AUTOSAR XML (schema 4-3-0)
package /DBCImport/CANTP
  can tp config CanTpConfig_BCAN: communication-cluster=BCAN, can-tp-ecu=SCM
    can tp channel CanTpChannel0: channel-id=0, channel-mode=HALF-DUPLEX-MODE
    can tp channel CanTpChannel2: channel-id=2, channel-mode=HALF-DUPLEX-MODE
    tp-connections:
      addressing-format=STANDARD, can-tp-channel=CanTpChannel0, data-pdu=NPdu_BCAN_RWPC_GST, flow-control-pdu=NPdu_BCAN_GST_RWPC, max-block-size=0, padding-activation=true, ta-type=PHYSICAL, tp-sdu=DcmIPdu_BCAN_RWPC_GST
      addressing-format=STANDARD, can-tp-channel=CanTpChannel0, data-pdu=NPdu_BCAN_GST_RWPC, flow-control-pdu=NPdu_BCAN_RWPC_GST, max-block-size=0, padding-activation=true, ta-type=PHYSICAL, tp-sdu=DcmIPdu_BCAN_GST_RWPC
      addressing-format=STANDARD, can-tp-channel=CanTpChannel2, data-pdu=NPdu_BCAN_GST_ALL, max-block-size=0, padding-activation=true, ta-type=FUNCTIONAL, tp-sdu=DcmIPdu_BCAN_GST_ALL
    can tp node SCM: connector=Conn_SCM_BCAN
package /DBCImport/SWCComposition
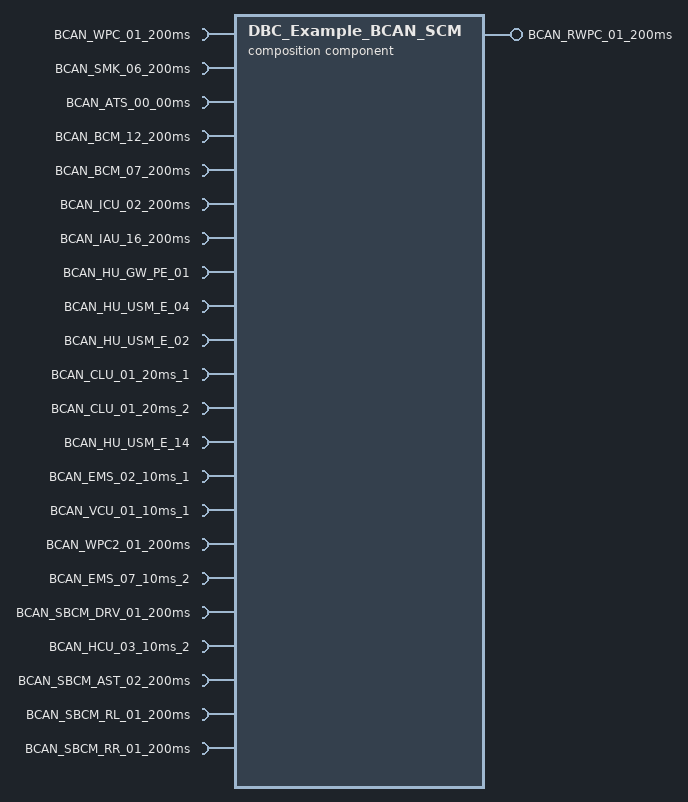
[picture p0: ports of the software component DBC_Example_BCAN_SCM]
  composition sw component type DBC_Example_BCAN_SCM
    provide port BCAN_RWPC_01_200ms: provided-interface=BCAN_RWPC_01_200ms
    22 x require port:
      BCAN_WPC_01_200ms: required-interface=BCAN_WPC_01_200ms
      BCAN_SMK_06_200ms: required-interface=BCAN_SMK_06_200ms
      BCAN_ATS_00_00ms: required-interface=BCAN_ATS_00_00ms
      BCAN_BCM_12_200ms: required-interface=BCAN_BCM_12_200ms
      BCAN_BCM_07_200ms: required-interface=BCAN_BCM_07_200ms
      BCAN_ICU_02_200ms: required-interface=BCAN_ICU_02_200ms
      BCAN_IAU_16_200ms: required-interface=BCAN_IAU_16_200ms
      BCAN_HU_GW_PE_01: required-interface=BCAN_HU_GW_PE_01
      BCAN_HU_USM_E_04: required-interface=BCAN_HU_USM_E_04
      BCAN_HU_USM_E_02: required-interface=BCAN_HU_USM_E_02
      BCAN_CLU_01_20ms_1: required-interface=BCAN_CLU_01_20ms_1
      BCAN_CLU_01_20ms_2: required-interface=BCAN_CLU_01_20ms_2
      BCAN_HU_USM_E_14: required-interface=BCAN_HU_USM_E_14
      BCAN_EMS_02_10ms_1: required-interface=BCAN_EMS_02_10ms_1
      BCAN_VCU_01_10ms_1: required-interface=BCAN_VCU_01_10ms_1
      BCAN_WPC2_01_200ms: required-interface=BCAN_WPC2_01_200ms
      BCAN_EMS_07_10ms_2: required-interface=BCAN_EMS_07_10ms_2
      BCAN_SBCM_DRV_01_200ms: required-interface=BCAN_SBCM_DRV_01_200ms
      BCAN_HCU_03_10ms_2: required-interface=BCAN_HCU_03_10ms_2
      BCAN_SBCM_AST_02_200ms: required-interface=BCAN_SBCM_AST_02_200ms
      BCAN_SBCM_RL_01_200ms: required-interface=BCAN_SBCM_RL_01_200ms
      BCAN_SBCM_RR_01_200ms: required-interface=BCAN_SBCM_RR_01_200ms
package /DBCImport/CLUSTERS
  can cluster BCAN: baudrate=500000, protocol-name=CAN, speed=500
    can physical channel BCAN: comm-connectors=Conn_SCM_BCAN
      frame CanFrame_BCAN_WPC_01_200ms: id 0x44B, frame-length=8, can-addressing-mode=STANDARD, can-fd-frame-support=false  # [PE] Periodic and On Event
        pdu ISignalIPdu_BCAN_WPC_01_200ms: length=8, minimum-delay=0.02, transmission-mode-true-timing={cyclic-timing={time-offset=0.0, time-period=0.2}, event-controlled-timing={number-of-repetitions=3, repetition-period=0.04}}
          signal ISignal_BCAN_WPC_01_200ms_WPC_IndSyncVal: start 40, 3 bit, little-endian, init-value=0, base-type=uint8, compu-method=ISignal_BCAN_WPC_01_200ms_WPC_IndSyncVal, transfer-property=TRIGGERED-ON-CHANGE
          signal ISignal_BCAN_WPC_01_200ms_USM_CmdWPCIndSta: start 43, 3 bit, little-endian, init-value=2, base-type=uint8, compu-method=ISignal_BCAN_WPC_01_200ms_USM_CmdWPCIndSta, transfer-property=TRIGGERED-ON-CHANGE
      frame CanFrame_BCAN_SMK_06_200ms: id 0x445, frame-length=8, can-addressing-mode=STANDARD, can-fd-frame-support=false  # [PE] Periodic and On Event
        pdu ISignalIPdu_BCAN_SMK_06_200ms: length=8, minimum-delay=0.02, transmission-mode-true-timing={cyclic-timing={time-offset=0.0, time-period=0.2}, event-controlled-timing={number-of-repetitions=3, repetition-period=0.04}}
          signal ISignal_BCAN_SMK_06_200ms_LFAnt_SrchSta: start 42, 2 bit, little-endian, init-value=0, base-type=uint8, compu-method=ISignal_BCAN_SMK_06_200ms_LFAnt_SrchSta, transfer-property=TRIGGERED-ON-CHANGE  # LFAntenna_SearchingStatus ##2G##SMK - SMKmsg19 - C_LFSearchingOn
      frame CanFrame_BCAN_ATS_00_00ms: id 0x447, frame-length=8, can-addressing-mode=STANDARD, can-fd-frame-support=false  # [EC] On Event and On Change
        pdu ISignalIPdu_BCAN_ATS_00_00ms: length=8, minimum-delay=0.02, transmission-mode-true-timing=event-controlled-timing={number-of-repetitions=3, repetition-period=0.04}
          signal ISignal_BCAN_ATS_00_00ms_ATS_RWPC_RWPCNValueSet: start 2, 3 bit, little-endian, init-value=0, base-type=uint8, compu {0=Default, 1=Off, 2=On, 3=Invalid, phys=raw for raw 0}, transfer-property=TRIGGERED-ON-CHANGE  # Rear Wireless Phone Charger ON/OFF Request
      frame CanFrame_BCAN_BCM_12_200ms: id 0x442, frame-length=8, can-addressing-mode=STANDARD, can-fd-frame-support=false  # [PE] Periodic and On Event
        pdu ISignalIPdu_BCAN_BCM_12_200ms: length=8, minimum-delay=0.02, transmission-mode-true-timing={cyclic-timing={time-offset=0.0, time-period=0.2}, event-controlled-timing={number-of-repetitions=3, repetition-period=0.04}}
          signal ISignal_BCAN_BCM_12_200ms_BCM_SmkOptTyp: start 24, 2 bit, little-endian, init-value=0, base-type=uint8, compu-method=ISignal_BCAN_BCM_12_200ms_BCM_SmkOptTyp, transfer-property=TRIGGERED-ON-CHANGE  # BCM_SmkOptionType ##2G##BCM - BCMmsg17 - C_SMKOption
      frame CanFrame_BCAN_BCM_07_200ms: id 0x41A, frame-length=8, can-addressing-mode=STANDARD, can-fd-frame-support=false  # [PE] Periodic and On Event
        pdu ISignalIPdu_BCAN_BCM_07_200ms: length=8, minimum-delay=0.02, transmission-mode-true-timing={cyclic-timing={time-offset=0.0, time-period=0.2}, event-controlled-timing={number-of-repetitions=3, repetition-period=0.04}}
          signal ISignal_BCAN_BCM_07_200ms_Lamp_IntTailLmpOnReq: start 36, 2 bit, little-endian, init-value=0, base-type=uint8, compu {0=Off, 1=On, 2=Not Used, 3=Error Indicator, phys=raw for raw 0}, transfer-property=TRIGGERED-ON-CHANGE  # Lamp_InternalTailLampOnRequest ##2G##BCM - BCMmsg19 - C_IntTailOn
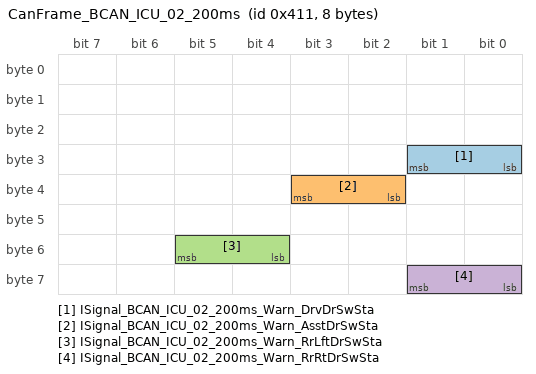
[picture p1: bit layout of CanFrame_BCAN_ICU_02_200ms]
      frame CanFrame_BCAN_ICU_02_200ms: id 0x411, frame-length=8, can-addressing-mode=STANDARD, can-fd-frame-support=false  # [PE] Periodic and On Event
        pdu ISignalIPdu_BCAN_ICU_02_200ms: length=8, minimum-delay=0.02, transmission-mode-true-timing={cyclic-timing={time-offset=0.0, time-period=0.2}, event-controlled-timing={number-of-repetitions=3, repetition-period=0.04}}
          signal ISignal_BCAN_ICU_02_200ms_Warn_DrvDrSwSta: start 24, 2 bit, little-endian, init-value=0, base-type=uint8, compu {0=Close, 1=Open, 2=Not Used, 3=Error Indicator, phys=raw for raw 0}, transfer-property=TRIGGERED-ON-CHANGE  # DoorLock_DriverDoorSwitchStatus ##2G## - - C_DrvDrSw,CF_Gway_DrvDrSw,Warn_DrvDrSwSta
          signal ISignal_BCAN_ICU_02_200ms_Warn_AsstDrSwSta: start 34, 2 bit, little-endian, init-value=0, base-type=uint8, compu {0=Close, 1=Open, 2=Not Used, 3=Error Indicator, phys=raw for raw 0}, transfer-property=TRIGGERED-ON-CHANGE  # Warn_AssistDoorSwitchStatus ##2G## - - C_AstDrSw,CF_Gway_AstDrSw,Warn_AsstDrSwSta
          signal ISignal_BCAN_ICU_02_200ms_Warn_RrLftDrSwSta: start 52, 2 bit, little-endian, init-value=0, base-type=uint8, compu {0=Close, 1=Open, 2=Not Used, 3=Error Indicator, phys=raw for raw 0}, transfer-property=TRIGGERED-ON-CHANGE  # Warn_RearLeftDoorSwitchStatus ##2G## - - C_RLDrSw,CF_Gway_RLDrSw,Warn_RrLftDrSwSta
          signal ISignal_BCAN_ICU_02_200ms_Warn_RrRtDrSwSta: start 56, 2 bit, little-endian, init-value=0, base-type=uint8, compu {0=Close, 1=Open, 2=Not Used, 3=Error Indicator, phys=raw for raw 0}, transfer-property=TRIGGERED-ON-CHANGE  # Warn_RearRightDoorSwitchStatus ##2G## - - C_RRDrSw,CF_Gway_RRDrSw,Warn_RrRtDrSwSta
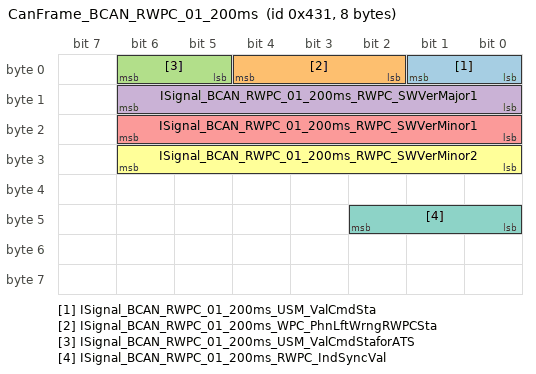
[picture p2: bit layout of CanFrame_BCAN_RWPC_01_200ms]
      frame CanFrame_BCAN_RWPC_01_200ms: id 0x431, frame-length=8, can-addressing-mode=STANDARD, can-fd-frame-support=false  # [PE] Periodic and On Event
        pdu ISignalIPdu_BCAN_RWPC_01_200ms: length=8, minimum-delay=0.02, transmission-mode-true-timing={cyclic-timing={time-offset=0.0, time-period=0.2}, event-controlled-timing={number-of-repetitions=3, repetition-period=0.04}}
          signal ISignal_BCAN_RWPC_01_200ms_USM_ValCmdSta: start 0, 2 bit, little-endian, init-value=0, base-type=uint8, compu {0=Default, 1=Off(Disable), 2=On(Enable), 3=Invalid, phys=raw for raw 0}, transfer-property=TRIGGERED-ON-CHANGE  # USM_ValueCommandStatus
          signal ISignal_BCAN_RWPC_01_200ms_WPC_PhnLftWrngRWPCSta: start 2, 3 bit, little-endian, init-value=0, base-type=uint8, compu-method=ISignal_BCAN_RWPC_01_200ms_WPC_PhnLftWrngRWPCSta, transfer-property=TRIGGERED-ON-CHANGE  # WPC_PhoneLeftWaringRWPCStatus
          signal ISignal_BCAN_RWPC_01_200ms_USM_ValCmdStaforATS: start 5, 2 bit, little-endian, init-value=0, base-type=uint8, compu {0=Default, 1=Off(Disable), 2=On(Enable), 3=Invalid, phys=raw for raw 0}, transfer-property=TRIGGERED-ON-CHANGE  # USM_ValueCommandStatus
          signal ISignal_BCAN_RWPC_01_200ms_RWPC_SWVerMajor1: start 8, 7 bit, little-endian, init-value=0, base-type=uint8, compu-method=ISignal_BCAN_RWPC_01_200ms_RWPC_SWVerMajor1, transfer-property=TRIGGERED-ON-CHANGE  # First Word(ASCII) in RWPC S/W Ver
          signal ISignal_BCAN_RWPC_01_200ms_RWPC_SWVerMinor1: start 16, 7 bit, little-endian, init-value=0, base-type=uint8, compu-method=ISignal_BCAN_RWPC_01_200ms_RWPC_SWVerMinor1, transfer-property=TRIGGERED-ON-CHANGE  # Second Word(ASCII) in RWPC S/W Ver
          signal ISignal_BCAN_RWPC_01_200ms_RWPC_SWVerMinor2: start 24, 7 bit, little-endian, init-value=0, base-type=uint8, compu-method=ISignal_BCAN_RWPC_01_200ms_RWPC_SWVerMinor2, transfer-property=TRIGGERED-ON-CHANGE  # Third Word(ASCII) in RWPC S/W Ver
          signal ISignal_BCAN_RWPC_01_200ms_RWPC_IndSyncVal: start 40, 3 bit, little-endian, init-value=0, base-type=uint8, compu-method=ISignal_BCAN_RWPC_01_200ms_RWPC_IndSyncVal, transfer-property=TRIGGERED-ON-CHANGE
      frame CanFrame_BCAN_IAU_16_200ms: id 0x434, frame-length=8, can-addressing-mode=STANDARD, can-fd-frame-support=false  # [PE] Periodic and On Event
        pdu ISignalIPdu_BCAN_IAU_16_200ms: length=8, minimum-delay=0.02, transmission-mode-true-timing={cyclic-timing={time-offset=0.0, time-period=0.2}, event-controlled-timing={number-of-repetitions=3, repetition-period=0.04}}
          signal ISignal_BCAN_IAU_16_200ms_IAU_ProfileIDRVal: start 10, 4 bit, little-endian, init-value=0, base-type=uint8, compu-method=ISignal_BCAN_IAU_16_200ms_IAU_ProfileIDRVal, transfer-property=TRIGGERED-ON-CHANGE  # This signal Indicate the Current detected Profile ID by IAU.
      frame CanFrame_BCAN_HU_GW_PE_01: id 0x4D8, frame-length=8, can-addressing-mode=STANDARD, can-fd-frame-support=false  # [PE] Periodic and On Event
        pdu ISignalIPdu_BCAN_HU_GW_PE_01: length=8, minimum-delay=0.02, transmission-mode-true-timing={cyclic-timing={time-offset=0.0, time-period=0.2}, event-controlled-timing={number-of-repetitions=3, repetition-period=0.04}}
          signal ISignal_BCAN_HU_GW_PE_01_CF_AVN_ProfileIDRValue: start 40, 4 bit, little-endian, init-value=15, base-type=uint8, compu-method=ISignal_BCAN_HU_GW_PE_01_CF_AVN_ProfileIDRValue, transfer-property=TRIGGERED-ON-CHANGE  # This signal is User ID value in H/Unit.
      frame CanFrame_BCAN_HU_USM_E_04: id 0x4AB, frame-length=8, can-addressing-mode=STANDARD, can-fd-frame-support=false  # [EC] On Event and On Change
        pdu ISignalIPdu_BCAN_HU_USM_E_04: length=8, minimum-delay=0.02, transmission-mode-true-timing=event-controlled-timing={number-of-repetitions=3, repetition-period=0.04}
          signal ISignal_BCAN_HU_USM_E_04_CF_AVN_CluUSMReset: start 62, 2 bit, little-endian, init-value=0, base-type=uint8, compu {0=Default, 1=USM Reset, 2=Reserved, 3=Invalid, phys=raw for raw 0}, transfer-property=TRIGGERED-ON-CHANGE  # Request to reset all USM service
      frame CanFrame_BCAN_HU_USM_E_02: id 0x4A9, frame-length=8, can-addressing-mode=STANDARD, can-fd-frame-support=false  # [EC] On Event and On Change
        pdu ISignalIPdu_BCAN_HU_USM_E_02: length=8, minimum-delay=0.02, transmission-mode-true-timing=event-controlled-timing={number-of-repetitions=3, repetition-period=0.04}
          signal ISignal_BCAN_HU_USM_E_02_CF_Gway_RWPCNValueSet: start 40, 2 bit, little-endian, init-value=0, base-type=uint8, compu {0=Default, 1=Off, 2=On, 3=Invalid, phys=raw for raw 0}, transfer-property=TRIGGERED-ON-CHANGE  # Rear Wireless Phone Charger ON/OFF Request
      frame CanFrame_BCAN_CLU_01_20ms_1: id 0x681AA01, frame-length=8, can-addressing-mode=EXTENDED, can-fd-frame-support=false  # [P] Periodic
        pdu ISignalIPdu_BCAN_CLU_01_20ms_1: length=8, minimum-delay=0.02, transmission-mode-true-timing=cyclic-timing={time-offset=0.0, time-period=0.1}
          signal ISignal_BCAN_CLU_01_20ms_1_CLU_DtntOutSta: start 28, 2 bit, little-endian, init-value=0, base-type=uint8, compu-method=ISignal_BCAN_CLU_01_20ms_1_CLU_DtntOutSta, transfer-property=PENDING  # CLU_DetentOutStatus
          signal ISignal_BCAN_CLU_01_20ms_1_CLU_RhstaLvlSta: start 43, 5 bit, little-endian, init-value=0, base-type=uint8, compu-method=ISignal_BCAN_CLU_01_20ms_1_CLU_RhstaLvlSta, transfer-property=PENDING  # CLU_RheostatLevelStatus
      frame CanFrame_BCAN_CLU_01_20ms_2: id 0x681AA02, frame-length=8, can-addressing-mode=EXTENDED, can-fd-frame-support=false  # [P] Periodic
        pdu ISignalIPdu_BCAN_CLU_01_20ms_2: length=8, minimum-delay=0.02, transmission-mode-true-timing=cyclic-timing={time-offset=0.0, time-period=0.1}
          signal ISignal_BCAN_CLU_01_20ms_2_CLU_DisSpdVal_KPH: start 0, 9 bit, little-endian, init-value=0, base-type=uint16, compu {511=Error, phys=raw for raw 0; unit km/h}, unit=km/h, transfer-property=PENDING  # CLU_DisplaySpeedValue_KPH
          signal ISignal_BCAN_CLU_01_20ms_2_CLU_AutoBrightSta: start 15, 8 bit, little-endian, init-value=0, base-type=uint8, compu-method=ISignal_BCAN_CLU_01_20ms_2_CLU_AutoBrightSta, transfer-property=PENDING  # CLU_AutoBrightStatus
      frame CanFrame_BCAN_HU_USM_E_14: id 0x1EB, frame-length=8, can-addressing-mode=STANDARD, can-fd-frame-support=false  # [EC] On Event and On Change
        pdu ISignalIPdu_BCAN_HU_USM_E_14: length=8, minimum-delay=0.02, transmission-mode-true-timing=event-controlled-timing={number-of-repetitions=3, repetition-period=0.04}
          signal ISignal_BCAN_HU_USM_E_14_CF_Gway_WPCAnimationNvalueSet: start 40, 3 bit, little-endian, init-value=0, base-type=uint8, compu-method=ISignal_BCAN_HU_USM_E_14_CF_Gway_WPCAnimationNvalueSet, transfer-property=TRIGGERED-ON-CHANGE
      frame CanFrame_BCAN_EMS_02_10ms_1: id 0x4010001, frame-length=8, can-addressing-mode=EXTENDED, can-fd-frame-support=false  # [P] Periodic
        pdu ISignalIPdu_BCAN_EMS_02_10ms_1: length=8, minimum-delay=0.02, transmission-mode-true-timing=cyclic-timing={time-offset=0.0, time-period=0.05}
          signal ISignal_BCAN_EMS_02_10ms_1_ENG_EngSta: start 61, 3 bit, little-endian, init-value=0, base-type=uint8, compu-method=ISignal_BCAN_EMS_02_10ms_1_ENG_EngSta, transfer-property=PENDING  # ENG_EngineStatus ##2G##EMS - EMS16 - ENG_STAT
      frame CanFrame_BCAN_VCU_01_10ms_1: id 0xC03501, frame-length=8, can-addressing-mode=EXTENDED, can-fd-frame-support=false  # [P] Periodic
        pdu ISignalIPdu_BCAN_VCU_01_10ms_1: length=8, minimum-delay=0.02, transmission-mode-true-timing=cyclic-timing={time-offset=0.0, time-period=0.05}
          signal ISignal_BCAN_VCU_01_10ms_1_VCU_EvDrvRdySta: start 28, 2 bit, little-endian, init-value=0, base-type=uint8, compu-method=ISignal_BCAN_VCU_01_10ms_1_VCU_EvDrvRdySta, transfer-property=PENDING  # VCU_EvDriveReadyStatus ##2G##VCU - VCU1 - CF_Vcu_EvRdy
      frame CanFrame_BCAN_WPC2_01_200ms: id 0x33E, frame-length=8, can-addressing-mode=STANDARD, can-fd-frame-support=false  # [PE] Periodic and On Event
        pdu ISignalIPdu_BCAN_WPC2_01_200ms: length=8, minimum-delay=0.02, transmission-mode-true-timing={cyclic-timing={time-offset=0.0, time-period=0.2}, event-controlled-timing={number-of-repetitions=3, repetition-period=0.04}}
          signal ISignal_BCAN_WPC2_01_200ms_WPC2_IndSyncVal: start 40, 3 bit, little-endian, init-value=0, base-type=uint8, compu-method=ISignal_BCAN_WPC2_01_200ms_WPC2_IndSyncVal, transfer-property=TRIGGERED-ON-CHANGE
      frame CanFrame_BCAN_EMS_07_10ms_2: id 0x4010502, frame-length=8, can-addressing-mode=EXTENDED, can-fd-frame-support=false  # [P] Periodic
        pdu ISignalIPdu_BCAN_EMS_07_10ms_2: length=8, minimum-delay=0.02, transmission-mode-true-timing=cyclic-timing={time-offset=0.0, time-period=0.05}
          signal ISignal_BCAN_EMS_07_10ms_2_HEV_EngOpSta: start 28, 3 bit, little-endian, init-value=0, base-type=uint8, compu-method=ISignal_BCAN_EMS_07_10ms_2_HEV_EngOpSta, transfer-property=PENDING  # HEV_EngineOperatingStatus
      frame CanFrame_BCAN_SBCM_DRV_01_200ms: id 0x31F, frame-length=8, can-addressing-mode=STANDARD, can-fd-frame-support=false  # [PE] Periodic and On Event
        pdu ISignalIPdu_BCAN_SBCM_DRV_01_200ms: length=8, minimum-delay=0.02, transmission-mode-true-timing={cyclic-timing={time-offset=0.0, time-period=0.2}, event-controlled-timing={number-of-repetitions=3, repetition-period=0.04}}
          signal ISignal_BCAN_SBCM_DRV_01_200ms_Warn_DrvDrSwSta_SBCM: start 20, 2 bit, little-endian, init-value=0, base-type=uint8, compu {0=Close, 1=Open, 2=RESERVED, 3=Error Indicator, phys=raw for raw 0}, transfer-property=TRIGGERED-ON-CHANGE  # DoorLock_DriverDoorSwitchStatus ##2G## - - C_DrvDrSw,CF_Gway_DrvDrSw,Warn_DrvDrSwSta
          signal ISignal_BCAN_SBCM_DRV_01_200ms_Latch_TypeOption_DRV: start 36, 2 bit, little-endian, init-value=0, base-type=uint8, compu {0=Off, 1=On, 2=RESERVED, 3=Error Indicator, phys=raw for raw 0}, transfer-property=TRIGGERED-ON-CHANGE
      frame CanFrame_BCAN_HCU_03_10ms_2: id 0x3C0FA02, frame-length=8, can-addressing-mode=EXTENDED, can-fd-frame-support=false  # [P] Periodic
        pdu ISignalIPdu_BCAN_HCU_03_10ms_2: length=8, minimum-delay=0.02, transmission-mode-true-timing=cyclic-timing={time-offset=0.0, time-period=0.05}
          signal ISignal_BCAN_HCU_03_10ms_2_HCU_HevRdySta: start 6, 2 bit, little-endian, init-value=0, base-type=uint8, compu-method=ISignal_BCAN_HCU_03_10ms_2_HCU_HevRdySta, transfer-property=PENDING  # HCU_HybridVehicleReadyStatus ##2G##HCU - HCU1 - CF_Hcu_HevRdy
      frame CanFrame_BCAN_RWPC_GST: id 0x72C, frame-length=8, can-addressing-mode=STANDARD, can-fd-frame-support=false
        dcm i pdu DcmIPdu_BCAN_RWPC_GST: length=8, diag-pdu-type=DIAG-RESPONSE
        n pdu NPdu_BCAN_RWPC_GST: length=8, meta-data-length=0
      frame CanFrame_BCAN_GST_RWPC: id 0x724, frame-length=8, can-addressing-mode=STANDARD, can-fd-frame-support=false
        dcm i pdu DcmIPdu_BCAN_GST_RWPC: length=8, diag-pdu-type=DIAG-REQUEST
        n pdu NPdu_BCAN_GST_RWPC: length=8, meta-data-length=0
      frame CanFrame_BCAN_SBCM_AST_02_200ms: id 0x35A, frame-length=8, can-addressing-mode=STANDARD, can-fd-frame-support=false  # [PE] Periodic and On Event
        pdu ISignalIPdu_BCAN_SBCM_AST_02_200ms: length=8, minimum-delay=0.02, transmission-mode-true-timing={cyclic-timing={time-offset=0.0, time-period=0.2}, event-controlled-timing={number-of-repetitions=3, repetition-period=0.04}}
          signal ISignal_BCAN_SBCM_AST_02_200ms_Warn_AsstDrSwSta_SBCM: start 20, 2 bit, little-endian, init-value=0, base-type=uint8, compu {0=Close, 1=Open, 2=RESERVED, 3=Error Indicator, phys=raw for raw 0}, transfer-property=TRIGGERED-ON-CHANGE  # Warn_AssistDoorSwitchStatus ##2G## - - C_AstDrSw,CF_Gway_AstDrSw,Warn_AsstDrSwSta
      frame CanFrame_BCAN_SBCM_RL_01_200ms: id 0x35E, frame-length=8, can-addressing-mode=STANDARD, can-fd-frame-support=false  # [PE] Periodic and On Event
        pdu ISignalIPdu_BCAN_SBCM_RL_01_200ms: length=8, minimum-delay=0.02, transmission-mode-true-timing={cyclic-timing={time-offset=0.0, time-period=0.2}, event-controlled-timing={number-of-repetitions=3, repetition-period=0.04}}
          signal ISignal_BCAN_SBCM_RL_01_200ms_Warn_RrLftDrSwSta_SBCM: start 16, 2 bit, little-endian, init-value=0, base-type=uint8, compu {0=Close, 1=Open, 2=RESERVED, 3=Error Indicator, phys=raw for raw 0}, transfer-property=TRIGGERED-ON-CHANGE  # Warn_RearLeftDoorSwitchStatus ##2G## - - C_RLDrSw,CF_Gway_RLDrSw,Warn_RrLftDrSwSta
      frame CanFrame_BCAN_GST_ALL: id 0x7DF, frame-length=8, can-addressing-mode=STANDARD, can-fd-frame-support=false
        dcm i pdu DcmIPdu_BCAN_GST_ALL: length=8
        n pdu NPdu_BCAN_GST_ALL: length=8, meta-data-length=0
      frame CanFrame_BCAN_SBCM_RR_01_200ms: id 0x389, frame-length=8, can-addressing-mode=STANDARD, can-fd-frame-support=false  # [PE] Periodic and On Event
        pdu ISignalIPdu_BCAN_SBCM_RR_01_200ms: length=8, minimum-delay=0.02, transmission-mode-true-timing={cyclic-timing={time-offset=0.0, time-period=0.2}, event-controlled-timing={number-of-repetitions=3, repetition-period=0.04}}
          signal ISignal_BCAN_SBCM_RR_01_200ms_Warn_RrRtDrSwSta_SBCM: start 16, 2 bit, little-endian, init-value=0, base-type=uint8, compu {0=Close, 1=Open, 2=RESERVED, 3=Error Indicator, phys=raw for raw 0}, transfer-property=TRIGGERED-ON-CHANGE  # Warn_RearRightDoorSwitchStatus ##2G## - - C_RRDrSw,CF_Gway_RRDrSw,Warn_RrRtDrSwSta
      frame CanFrame_BCAN_NM_WPC2: id 0x515, frame-length=8, can-addressing-mode=STANDARD, can-fd-frame-support=false
        user defined pdu UserDefinedPdu_BCAN_NM_WPC2: length=8, cdd-type=OsekNm
      frame CanFrame_BCAN_NM_PSB: id 0x541, frame-length=8, can-addressing-mode=STANDARD, can-fd-frame-support=false
        user defined pdu UserDefinedPdu_BCAN_NM_PSB: length=8, cdd-type=OsekNm
      frame CanFrame_BCAN_NM_SHVU_RR: id 0x52B, frame-length=8, can-addressing-mode=STANDARD, can-fd-frame-support=false
        user defined pdu UserDefinedPdu_BCAN_NM_SHVU_RR: length=8, cdd-type=OsekNm
      frame CanFrame_BCAN_NM_FCS: id 0x521, frame-length=8, can-addressing-mode=STANDARD, can-fd-frame-support=false
        user defined pdu UserDefinedPdu_BCAN_NM_FCS: length=8, cdd-type=OsekNm
      frame CanFrame_BCAN_NM_EMCU: id 0x511, frame-length=8, can-addressing-mode=STANDARD, can-fd-frame-support=false
        user defined pdu UserDefinedPdu_BCAN_NM_EMCU: length=8, cdd-type=OsekNm
      frame CanFrame_BCAN_NM_SLB: id 0x51B, frame-length=8, can-addressing-mode=STANDARD, can-fd-frame-support=false
        user defined pdu UserDefinedPdu_BCAN_NM_SLB: length=8, cdd-type=OsekNm
      frame CanFrame_BCAN_NM_GW_APSU: id 0x531, frame-length=8, can-addressing-mode=STANDARD, can-fd-frame-support=false
        user defined pdu UserDefinedPdu_BCAN_NM_GW_APSU: length=8, cdd-type=OsekNm
      frame CanFrame_BCAN_NM_GW_DLBCU: id 0x540, frame-length=8, can-addressing-mode=STANDARD, can-fd-frame-support=false
        user defined pdu UserDefinedPdu_BCAN_NM_GW_DLBCU: length=8, cdd-type=OsekNm
      frame CanFrame_BCAN_NM_RCM: id 0x53D, frame-length=8, can-addressing-mode=STANDARD, can-fd-frame-support=false
        user defined pdu UserDefinedPdu_BCAN_NM_RCM: length=8, cdd-type=OsekNm
      frame CanFrame_BCAN_NM_ARS: id 0x50A, frame-length=8, can-addressing-mode=STANDARD, can-fd-frame-support=false
        user defined pdu UserDefinedPdu_BCAN_NM_ARS: length=8, cdd-type=OsekNm
      frame CanFrame_BCAN_NM_CGW_CCU: id 0x570, frame-length=8, can-addressing-mode=STANDARD, can-fd-frame-support=false
        user defined pdu UserDefinedPdu_BCAN_NM_CGW_CCU: length=8, cdd-type=OsekNm
      frame CanFrame_BCAN_NM_GW_RLPSU: id 0x51C, frame-length=8, can-addressing-mode=STANDARD, can-fd-frame-support=false
        user defined pdu UserDefinedPdu_BCAN_NM_GW_RLPSU: length=8, cdd-type=OsekNm
      frame CanFrame_BCAN_NM_ATS: id 0x550, frame-length=8, can-addressing-mode=STANDARD, can-fd-frame-support=false
        user defined pdu UserDefinedPdu_BCAN_NM_ATS: length=8, cdd-type=OsekNm
      frame CanFrame_BCAN_NM_RLHV: id 0x534, frame-length=8, can-addressing-mode=STANDARD, can-fd-frame-support=false
        user defined pdu UserDefinedPdu_BCAN_NM_RLHV: length=8, cdd-type=OsekNm
      frame CanFrame_BCAN_NM_SGU: id 0x53E, frame-length=8, can-addressing-mode=STANDARD, can-fd-frame-support=false
        user defined pdu UserDefinedPdu_BCAN_NM_SGU: length=8, cdd-type=OsekNm
      frame CanFrame_BCAN_NM_PFSU: id 0x52D, frame-length=8, can-addressing-mode=STANDARD, can-fd-frame-support=false
        user defined pdu UserDefinedPdu_BCAN_NM_PFSU: length=8, cdd-type=OsekNm
      frame CanFrame_BCAN_NM_GW_RRPSU: id 0x51D, frame-length=8, can-addressing-mode=STANDARD, can-fd-frame-support=false
        user defined pdu UserDefinedPdu_BCAN_NM_GW_RRPSU: length=8, cdd-type=OsekNm
      frame CanFrame_BCAN_NM_ALBCU: id 0x544, frame-length=8, can-addressing-mode=STANDARD, can-fd-frame-support=false
        user defined pdu UserDefinedPdu_BCAN_NM_ALBCU: length=8, cdd-type=OsekNm
      frame CanFrame_BCAN_NM_DSAU: id 0x559, frame-length=8, can-addressing-mode=STANDARD, can-fd-frame-support=false
        user defined pdu UserDefinedPdu_BCAN_NM_DSAU: length=8, cdd-type=OsekNm
      frame CanFrame_BCAN_NM_SWRC: id 0x508, frame-length=8, can-addressing-mode=STANDARD, can-fd-frame-support=false
        user defined pdu UserDefinedPdu_BCAN_NM_SWRC: length=8, cdd-type=OsekNm
      frame CanFrame_BCAN_NM_SHVU_FR: id 0x52A, frame-length=8, can-addressing-mode=STANDARD, can-fd-frame-support=false
        user defined pdu UserDefinedPdu_BCAN_NM_SHVU_FR: length=8, cdd-type=OsekNm
      frame CanFrame_BCAN_NM_RCS: id 0x546, frame-length=8, can-addressing-mode=STANDARD, can-fd-frame-support=false
        user defined pdu UserDefinedPdu_BCAN_NM_RCS: length=8, cdd-type=OsekNm
      frame CanFrame_BCAN_NM_GW_DPSU: id 0x538, frame-length=8, can-addressing-mode=STANDARD, can-fd-frame-support=false
        user defined pdu UserDefinedPdu_BCAN_NM_GW_DPSU: length=8, cdd-type=OsekNm
      frame CanFrame_BCAN_NM_BLTN_CAM: id 0x548, frame-length=8, can-addressing-mode=STANDARD, can-fd-frame-support=false
        user defined pdu UserDefinedPdu_BCAN_NM_BLTN_CAM: length=8, cdd-type=OsekNm
      frame CanFrame_BCAN_NM_SCM: id 0x507, frame-length=8, can-addressing-mode=STANDARD, can-fd-frame-support=false
        user defined pdu UserDefinedPdu_BCAN_NM_SCM: length=8, cdd-type=OsekNm
      frame CanFrame_BCAN_NM_OHCL: id 0x554, frame-length=8, can-addressing-mode=STANDARD, can-fd-frame-support=false
        user defined pdu UserDefinedPdu_BCAN_NM_OHCL: length=8, cdd-type=OsekNm
      frame CanFrame_BCAN_NM_RWPC: id 0x51F, frame-length=8, can-addressing-mode=STANDARD, can-fd-frame-support=false
        user defined pdu UserDefinedPdu_BCAN_NM_RWPC: length=8, cdd-type=OsekNm
      frame CanFrame_BCAN_NM_RRHV: id 0x535, frame-length=8, can-addressing-mode=STANDARD, can-fd-frame-support=false
        user defined pdu UserDefinedPdu_BCAN_NM_RRHV: length=8, cdd-type=OsekNm
      frame CanFrame_BCAN_NM_WPC: id 0x51E, frame-length=8, can-addressing-mode=STANDARD, can-fd-frame-support=false
        user defined pdu UserDefinedPdu_BCAN_NM_WPC: length=8, cdd-type=OsekNm
      frame CanFrame_BCAN_NM_HOD: id 0x54A, frame-length=8, can-addressing-mode=STANDARD, can-fd-frame-support=false
        user defined pdu UserDefinedPdu_BCAN_NM_HOD: length=8, cdd-type=OsekNm
      frame CanFrame_BCAN_NM_ASAU: id 0x553, frame-length=8, can-addressing-mode=STANDARD, can-fd-frame-support=false
        user defined pdu UserDefinedPdu_BCAN_NM_ASAU: length=8, cdd-type=OsekNm
package /DBCImport/COMPUMETHODS
  compu method ISignal_BCAN_BCM_12_200ms_BCM_SmkOptTyp: 0=Non SMK Option, 1=SMK Option, 2=Not Used, 3=Error Indicator, phys=raw for raw 0
  compu method ISignal_BCAN_CLU_01_20ms_1_CLU_DtntOutSta: 0=Detent Off, 1=Detent On, 2=Not used, 3=Error Indicator, phys=raw for raw 0
  compu method ISignal_BCAN_CLU_01_20ms_1_CLU_RhstaLvlSta: 0=Reserved, 1..19=Step 1..Step 19, 20=Step 20 (Reset Value), 21=Step 21 (Detent), phys=raw for raw 0
  compu method ISignal_BCAN_CLU_01_20ms_2_CLU_AutoBrightSta: 0=Reserved (Not Used), 1=0x01~0xC8:Bright State (1~200 Step), 200=0x01~0xC8:Bright State (1~200 Step), phys=raw for raw 0
  compu method ISignal_BCAN_EMS_02_10ms_1_ENG_EngSta: 0=Engine Stop, 1=Cranking, 2=Stalled, 3=Running, 4=Reserved, 5=Reserved, 6=Reserved, 7=Fault, phys=raw for raw 0
  compu method ISignal_BCAN_EMS_07_10ms_2_HEV_EngOpSta: 0=ES(Engine Stop), 1=ST(Start), 2=IS(Idle speed), 3=PL(Part Load), 4=PU(Pull), 5=PUC(Fuel Cut off), phys=raw for raw 0
  compu method ISignal_BCAN_HCU_03_10ms_2_HCU_HevRdySta: 0=HEV not ready, 1=HEV Drivable, 2=Not used, 3=Error Indicator, phys=raw for raw 0
  compu method ISignal_BCAN_HU_GW_PE_01_CF_AVN_ProfileIDRValue: 0=Default, 1=Guest, 2..10=Profile 1..Profile 9, 11..14=RESERVED, 15=Invalid, phys=raw for raw 0
  compu method ISignal_BCAN_HU_USM_E_14_CF_Gway_WPCAnimationNvalueSet: 0=Default, 1=Type 1 (Animation Off), 2=Type 2 (Animation On), 3..6=Reserved, 7=Invalid, phys=raw for raw 0
  compu method ISignal_BCAN_IAU_16_200ms_IAU_ProfileIDRVal: 0=Default, 1=Guest, 2..10=Profile1..Profile9, 11..14=RESERVED, 15=INVALID, phys=raw for raw 0
  compu method ISignal_BCAN_RWPC_01_200ms_RWPC_IndSyncVal: 0=default, 1=off, 2=1st sync, 3=2nd sync, 4=3rd sync, 5=error off, 6=error on, 7=reserved, phys=raw for raw 0
  compu method ISignal_BCAN_RWPC_01_200ms_RWPC_SWVerMajor1: 0=0x0x0~0x7F:ASCII Code Value (HEX), 127=0x0x0~0x7F:ASCII Code Value (HEX), phys=raw for raw 0
  compu method ISignal_BCAN_RWPC_01_200ms_RWPC_SWVerMinor1: 0=0x0x0~0x7F:ASCII Code Value (HEX), 127=0x0x0~0x7F:ASCII Code Value (HEX), phys=raw for raw 0
  compu method ISignal_BCAN_RWPC_01_200ms_RWPC_SWVerMinor2: 0=0x0x0~0x7F:ASCII Code Value (HEX), 127=0x0x0~0x7F:ASCII Code Value (HEX), phys=raw for raw 0
  compu method ISignal_BCAN_RWPC_01_200ms_WPC_PhnLftWrngRWPCSta: 0=Off, 1=Cellphone on the pad, 2=Charging, 3=Charging complete, 4=Cellphone reminder, 5=Error, 6=NFC Card detected, 7=Invalid, phys=raw for raw 0
  compu method ISignal_BCAN_SMK_06_200ms_LFAnt_SrchSta: 0=Off, 1=On (LF Searching), 2=Not Used, 3=Error Indicator, phys=raw for raw 0
  compu method ISignal_BCAN_VCU_01_10ms_1_VCU_EvDrvRdySta: 0=None, 1=EV Drivable, 2=Not used, 3=Error Indicator, phys=raw for raw 0..3
  compu method ISignal_BCAN_WPC2_01_200ms_WPC2_IndSyncVal: 0=default, 1=off, 2=1st sync, 3=2nd sync, 4=3rd sync, 5=error off, 6=error on, 7=reserved, phys=raw for raw 0
  compu method ISignal_BCAN_WPC_01_200ms_USM_CmdWPCIndSta: 0=Default, 1=Type 1 (Animation Off), 2=Type 2 (Animation On), 3..6=RESERVED, 7=Invalid, phys=raw for raw 0
  compu method ISignal_BCAN_WPC_01_200ms_WPC_IndSyncVal: 0=default, 1=off, 2=1st sync, 3=2nd sync, 4=3rd sync, 5=error off, 6=error on, 7=reserved, phys=raw for raw 0
package /DBCImport/IPDUGROUPS
  i signal i pdu group ISignalIPduGroupRx_SCM_BCAN: communication-direction=IN, communication-mode=rx
    i-signal-i-pdus:
      ISignalIPdu_BCAN_WPC_01_200ms
      ISignalIPdu_BCAN_SMK_06_200ms
      ISignalIPdu_BCAN_ATS_00_00ms
      ISignalIPdu_BCAN_BCM_12_200ms
      ISignalIPdu_BCAN_BCM_07_200ms
      ISignalIPdu_BCAN_ICU_02_200ms
      ISignalIPdu_BCAN_IAU_16_200ms
      ISignalIPdu_BCAN_HU_GW_PE_01
      ISignalIPdu_BCAN_HU_USM_E_04
      ISignalIPdu_BCAN_HU_USM_E_02
      ISignalIPdu_BCAN_CLU_01_20ms_1
      ISignalIPdu_BCAN_CLU_01_20ms_2
      ISignalIPdu_BCAN_HU_USM_E_14
      ISignalIPdu_BCAN_EMS_02_10ms_1
      ISignalIPdu_BCAN_VCU_01_10ms_1
      ISignalIPdu_BCAN_WPC2_01_200ms
      ISignalIPdu_BCAN_EMS_07_10ms_2
      ISignalIPdu_BCAN_SBCM_DRV_01_200ms
      ISignalIPdu_BCAN_HCU_03_10ms_2
      ISignalIPdu_BCAN_SBCM_AST_02_200ms
      ISignalIPdu_BCAN_SBCM_RL_01_200ms
      ISignalIPdu_BCAN_SBCM_RR_01_200ms
  i signal i pdu group ISignalIPduGroupTx_SCM_BCAN: communication-direction=OUT, communication-mode=tx, i-signal-i-pdus=ISignalIPdu_BCAN_RWPC_01_200ms
package /DBCImport/INTERFACES
  23 x sender receiver interface:
    BCAN_ATS_00_00ms
      data ATS_RWPC_RWPCNValueSet: base-type=uint8, compu {0=Default, 1=Off, 2=On, 3=Invalid, phys=raw for raw 0}, type=uint8, init-value=0
    BCAN_BCM_07_200ms
      data Lamp_IntTailLmpOnReq: base-type=uint8, compu {0=Off, 1=On, 2=Not Used, 3=Error Indicator, phys=raw for raw 0}, type=uint8, init-value=0
    BCAN_BCM_12_200ms
      data BCM_SmkOptTyp: base-type=uint8, compu-method=ISignal_BCAN_BCM_12_200ms_BCM_SmkOptTyp, type=uint8, init-value=0
    BCAN_CLU_01_20ms_1
      data CLU_DtntOutSta: base-type=uint8, compu-method=ISignal_BCAN_CLU_01_20ms_1_CLU_DtntOutSta, type=uint8, init-value=0
      data CLU_RhstaLvlSta: base-type=uint8, compu-method=ISignal_BCAN_CLU_01_20ms_1_CLU_RhstaLvlSta, type=uint8, init-value=0
    BCAN_CLU_01_20ms_2
      data CLU_DisSpdVal_KPH: base-type=uint16, compu {511=Error, phys=raw for raw 0; unit km/h}, unit=km/h, type=uint16, init-value=0
      data CLU_AutoBrightSta: base-type=uint8, compu-method=ISignal_BCAN_CLU_01_20ms_2_CLU_AutoBrightSta, type=uint8, init-value=0
    BCAN_EMS_02_10ms_1
      data ENG_EngSta: base-type=uint8, compu-method=ISignal_BCAN_EMS_02_10ms_1_ENG_EngSta, type=uint8, init-value=0
    BCAN_EMS_07_10ms_2
      data HEV_EngOpSta: base-type=uint8, compu-method=ISignal_BCAN_EMS_07_10ms_2_HEV_EngOpSta, type=uint8, init-value=0
    BCAN_HCU_03_10ms_2
      data HCU_HevRdySta: base-type=uint8, compu-method=ISignal_BCAN_HCU_03_10ms_2_HCU_HevRdySta, type=uint8, init-value=0
    BCAN_HU_GW_PE_01
      data CF_AVN_ProfileIDRValue: base-type=uint8, compu-method=ISignal_BCAN_HU_GW_PE_01_CF_AVN_ProfileIDRValue, type=uint8, init-value=15
    BCAN_HU_USM_E_02
      data CF_Gway_RWPCNValueSet: base-type=uint8, compu {0=Default, 1=Off, 2=On, 3=Invalid, phys=raw for raw 0}, type=uint8, init-value=0
    BCAN_HU_USM_E_04
      data CF_AVN_CluUSMReset: base-type=uint8, compu {0=Default, 1=USM Reset, 2=Reserved, 3=Invalid, phys=raw for raw 0}, type=uint8, init-value=0
    BCAN_HU_USM_E_14
      data CF_Gway_WPCAnimationNvalueSet: base-type=uint8, compu-method=ISignal_BCAN_HU_USM_E_14_CF_Gway_WPCAnimationNvalueSet, type=uint8, init-value=0
    BCAN_IAU_16_200ms
      data IAU_ProfileIDRVal: base-type=uint8, compu-method=ISignal_BCAN_IAU_16_200ms_IAU_ProfileIDRVal, type=uint8, init-value=0
    BCAN_ICU_02_200ms
      4 x data, all with base-type=uint8, compu {0=Close, 1=Open, 2=Not Used, 3=Error Indicator, phys=raw for raw 0}, type=uint8, init-value=0:
        Warn_DrvDrSwSta
        Warn_AsstDrSwSta
        Warn_RrLftDrSwSta
        Warn_RrRtDrSwSta
    BCAN_RWPC_01_200ms
      7 x data, all with base-type=uint8, type=uint8, init-value=0:
        USM_ValCmdSta: compu {0=Default, 1=Off(Disable), 2=On(Enable), 3=Invalid, phys=raw for raw 0}
        RWPC_SWVerMinor1: compu-method=ISignal_BCAN_RWPC_01_200ms_RWPC_SWVerMinor1
        WPC_PhnLftWrngRWPCSta: compu-method=ISignal_BCAN_RWPC_01_200ms_WPC_PhnLftWrngRWPCSta
        RWPC_SWVerMinor2: compu-method=ISignal_BCAN_RWPC_01_200ms_RWPC_SWVerMinor2
        RWPC_IndSyncVal: compu-method=ISignal_BCAN_RWPC_01_200ms_RWPC_IndSyncVal
        USM_ValCmdStaforATS: compu {0=Default, 1=Off(Disable), 2=On(Enable), 3=Invalid, phys=raw for raw 0}
        RWPC_SWVerMajor1: compu-method=ISignal_BCAN_RWPC_01_200ms_RWPC_SWVerMajor1
    BCAN_SBCM_AST_02_200ms
      data Warn_AsstDrSwSta_SBCM: base-type=uint8, compu {0=Close, 1=Open, 2=RESERVED, 3=Error Indicator, phys=raw for raw 0}, type=uint8, init-value=0
    BCAN_SBCM_DRV_01_200ms
      data Warn_DrvDrSwSta_SBCM: base-type=uint8, compu {0=Close, 1=Open, 2=RESERVED, 3=Error Indicator, phys=raw for raw 0}, type=uint8, init-value=0
      data Latch_TypeOption_DRV: base-type=uint8, compu {0=Off, 1=On, 2=RESERVED, 3=Error Indicator, phys=raw for raw 0}, type=uint8, init-value=0
    BCAN_SBCM_RL_01_200ms
      data Warn_RrLftDrSwSta_SBCM: base-type=uint8, compu {0=Close, 1=Open, 2=RESERVED, 3=Error Indicator, phys=raw for raw 0}, type=uint8, init-value=0
    BCAN_SBCM_RR_01_200ms
      data Warn_RrRtDrSwSta_SBCM: base-type=uint8, compu {0=Close, 1=Open, 2=RESERVED, 3=Error Indicator, phys=raw for raw 0}, type=uint8, init-value=0
    BCAN_SMK_06_200ms
      data LFAnt_SrchSta: base-type=uint8, compu-method=ISignal_BCAN_SMK_06_200ms_LFAnt_SrchSta, type=uint8, init-value=0
    BCAN_VCU_01_10ms_1
      data VCU_EvDrvRdySta: base-type=uint8, compu-method=ISignal_BCAN_VCU_01_10ms_1_VCU_EvDrvRdySta, type=uint8, init-value=0
    BCAN_WPC2_01_200ms
      data WPC2_IndSyncVal: base-type=uint8, compu-method=ISignal_BCAN_WPC2_01_200ms_WPC2_IndSyncVal, type=uint8, init-value=0
    BCAN_WPC_01_200ms
      data WPC_IndSyncVal: base-type=uint8, compu-method=ISignal_BCAN_WPC_01_200ms_WPC_IndSyncVal, type=uint8, init-value=0
      data USM_CmdWPCIndSta: base-type=uint8, compu-method=ISignal_BCAN_WPC_01_200ms_USM_CmdWPCIndSta, type=uint8, init-value=2
package /DBCImport/UNITS_BCAN
  unit Unit_km_per_h: display-name=km/h
